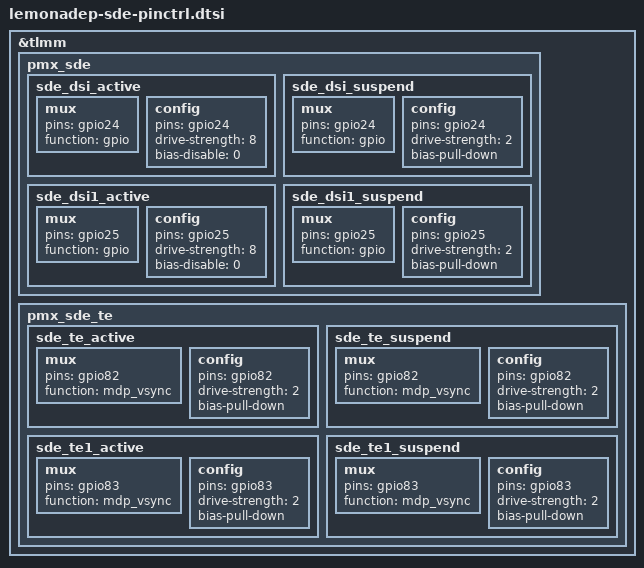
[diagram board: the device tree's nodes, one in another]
// SPDX-License-Identifier: BSD-3-Clause
/* lemonadep display reset/TE pinctrl, from stock Lahaina. */
&tlmm {
	pmx_sde: pmx_sde {
		sde_dsi_active: sde_dsi_active {
			mux { pins = "gpio24"; function = "gpio"; };
			config { pins = "gpio24"; drive-strength = <8>; bias-disable = <0>; };
		};
		sde_dsi_suspend: sde_dsi_suspend {
			mux { pins = "gpio24"; function = "gpio"; };
			config { pins = "gpio24"; drive-strength = <2>; bias-pull-down; };
		};
		sde_dsi1_active: sde_dsi1_active {
			mux { pins = "gpio25"; function = "gpio"; };
			config { pins = "gpio25"; drive-strength = <8>; bias-disable = <0>; };
		};
		sde_dsi1_suspend: sde_dsi1_suspend {
			mux { pins = "gpio25"; function = "gpio"; };
			config { pins = "gpio25"; drive-strength = <2>; bias-pull-down; };
		};
	};

	pmx_sde_te: pmx_sde_te {
		sde_te_active: sde_te_active {
			mux { pins = "gpio82"; function = "mdp_vsync"; };
			config { pins = "gpio82"; drive-strength = <2>; bias-pull-down; };
		};
		sde_te_suspend: sde_te_suspend {
			mux { pins = "gpio82"; function = "mdp_vsync"; };
			config { pins = "gpio82"; drive-strength = <2>; bias-pull-down; };
		};
		sde_te1_active: sde_te1_active {
			mux { pins = "gpio83"; function = "mdp_vsync"; };
			config { pins = "gpio83"; drive-strength = <2>; bias-pull-down; };
		};
		sde_te1_suspend: sde_te1_suspend {
			mux { pins = "gpio83"; function = "mdp_vsync"; };
			config { pins = "gpio83"; drive-strength = <2>; bias-pull-down; };
		};
	};
};
